AUTOSAR XML (schema 4.0)
package /YuleTech/PortInterfaces
  sender receiver interface VehicleSpeed_I
    data Speed: type=uint16, sw-calibration-access=READ-WRITE
  sender receiver interface SeatPosition_I
    data Position: type=sint16, sw-calibration-access=READ-WRITE
    data ReclineAngle: type=uint8, sw-calibration-access=READ-WRITE
  client server interface SeatControl_I
    operation AdjustPosition
      arg TargetPosition: type=sint16, direction=IN
      arg Result: type=boolean, direction=OUT
    operation StoreMemoryPosition
      arg SlotNumber: type=uint8, direction=IN
      arg Result: type=boolean, direction=OUT
package /YuleTech/SwComponents
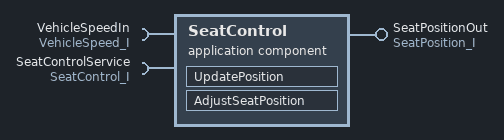
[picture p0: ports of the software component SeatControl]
  application sw component type SeatControl
    provide port SeatPositionOut: provided-interface=SeatPosition_I
    require port VehicleSpeedIn: required-interface=VehicleSpeed_I
    require port SeatControlService: required-interface=SeatControl_I
    behavior SeatControl_Behavior
      runnable UpdatePosition: minimum-start-interval=0.01, symbol=SeatControl_UpdatePosition
        data-read-access:
          access SpeedIn: accessed-variable=VehicleSpeedIn.Speed
        data-write-access:
          access PositionOut: accessed-variable=SeatPositionOut.Position
        event timing event TimingEvent_10ms: timing-offset=0.0, timing-period=0.01
      runnable AdjustSeatPosition: symbol=SeatControl_AdjustPosition
        sync call AdjustPositionCall: operation=SeatControlService.AdjustPosition
        event timing event TimingEvent_100ms: timing-offset=0.0, timing-period=0.1
  composition sw component type SeatSystem: components=SeatControl
    provide port ExternalSpeedIn: provided-interface=VehicleSpeed_I
    connect SeatSystem.ExternalSpeedIn -> SeatControl.VehicleSpeedIn
